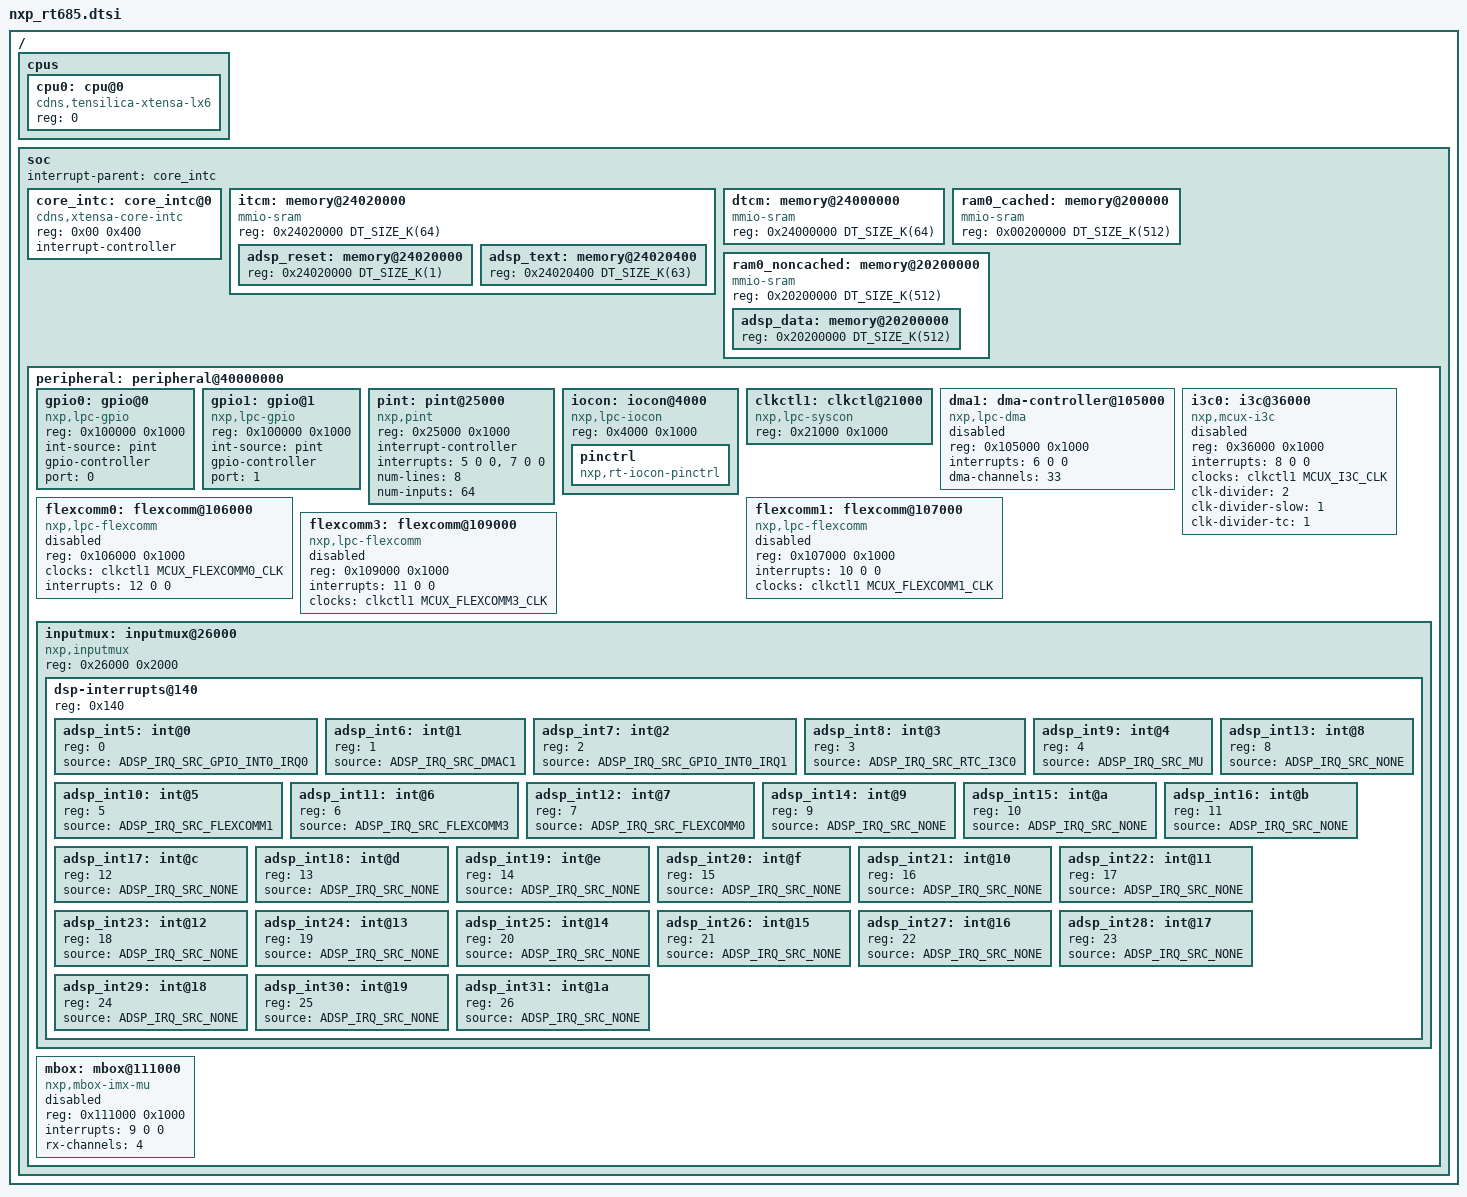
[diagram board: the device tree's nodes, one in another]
/*
 * Copyright (c) 2023 NXP.
 * SPDX-License-Identifier: Apache-2.0
 */

#include <xtensa/xtensa.dtsi>
#include <mem.h>
#include <zephyr/dt-bindings/clock/mcux_lpc_syscon_clock.h>
#include <zephyr/dt-bindings/misc/nxp-inputmux-rt6xx.h>
#include <zephyr/dt-bindings/input/input-event-codes.h>

/ {
	cpus {
		#address-cells = <1>;
		#size-cells = <0>;

		cpu0: cpu@0 {
			device_type = "cpu";
			compatible = "cdns,tensilica-xtensa-lx6";
			reg = <0>;
		};
	};

	soc {
		interrupt-parent = <&core_intc>;

		/*
		 * Dummy interrupt controller node - IRQs are handled directly by soc.c if
		 * building for the RT685 DSP.
		 *
		 * Be sure to configure the inputmux node for appropriate interrupt routing.
		 */
		core_intc: core_intc@0 {
			compatible = "cdns,xtensa-core-intc";
			reg = <0x00 0x400>;
			interrupt-controller;
			#interrupt-cells = <3>;
		};

		itcm: memory@24020000 {
			#address-cells = <1>;
			#size-cells = <1>;
			device_type = "memory";
			compatible = "mmio-sram";

			reg = <0x24020000 DT_SIZE_K(64)>;

			adsp_reset: memory@24020000 {
				reg = <0x24020000 DT_SIZE_K(1)>;
			};

			adsp_text: memory@24020400 {
				reg = <0x24020400 DT_SIZE_K(63)>;
			};
		};

		dtcm: memory@24000000 {
			#address-cells = <1>;
			#size-cells = <1>;
			device_type = "memory";
			compatible = "mmio-sram";

			reg = <0x24000000 DT_SIZE_K(64)>;

			/*adsp_data: memory@24000000 {
				reg = <0x24000000 DT_SIZE_K(64)>;
			};*/
		};

		ram0_cached: memory@200000 {
			#address-cells = <1>;
			#size-cells = <1>;
			device_type = "memory";
			compatible = "mmio-sram";

			reg = <0x00200000 DT_SIZE_K(512)>;

			/*adsp_data: memory@200000 {
				reg = <0x00200000 DT_SIZE_K(512)>;
			};*/
		};

		ram0_noncached: memory@20200000 {
			#address-cells = <1>;
			#size-cells = <1>;
			device_type = "memory";
			compatible = "mmio-sram";

			reg = <0x20200000 DT_SIZE_K(512)>;

			adsp_data: memory@20200000 {
				reg = <0x20200000 DT_SIZE_K(512)>;
			};
		};

		peripheral: peripheral@40000000 {
			ranges = <0x0 0x40000000 0x10000000>;

			#address-cells = <1>;
			#size-cells = <1>;

			gpio0: gpio@0 {
				compatible = "nxp,lpc-gpio";
				reg = <0x100000 0x1000>;
				int-source = "pint";
				gpio-controller;
				#gpio-cells = <2>;
				port = <0>;
			};

			gpio1: gpio@1 {
				compatible = "nxp,lpc-gpio";
				reg = <0x100000 0x1000>;
				int-source = "pint";
				gpio-controller;
				#gpio-cells = <2>;
				port = <1>;
			};

			pint: pint@25000 {
				compatible = "nxp,pint";
				reg = <0x25000 0x1000>;
				interrupt-controller;
				#interrupt-cells = <1>;
				#address-cells = <0>;
				interrupts = <5 0 0>, <7 0 0>;
				num-lines = <8>;
				num-inputs = <64>;
			};

			iocon: iocon@4000 {
				compatible = "nxp,lpc-iocon";
				reg = <0x4000 0x1000>;
				pinctrl: pinctrl {
					compatible = "nxp,rt-iocon-pinctrl";
				};
			};

			clkctl1: clkctl@21000 {
				compatible = "nxp,lpc-syscon";
				reg = <0x21000 0x1000>;
				#clock-cells = <1>;
			};

			dma1: dma-controller@105000 {
				compatible = "nxp,lpc-dma";
				reg = <0x105000 0x1000>;
				interrupts = <6 0 0>;
				dma-channels = <33>;
				status = "disabled";
				#dma-cells = <1>;
			};

			i3c0: i3c@36000 {
				compatible = "nxp,mcux-i3c";
				reg = <0x36000 0x1000>;
				#address-cells = <3>;
				#size-cells = <0>;
				interrupts = <8 0 0>;
				clocks = <&clkctl1 MCUX_I3C_CLK>;
				clk-divider = <2>;
				clk-divider-slow = <1>;
				clk-divider-tc = <1>;
				status = "disabled";
			};

			flexcomm0: flexcomm@106000 {
				compatible = "nxp,lpc-flexcomm";
				reg = <0x106000 0x1000>;
				clocks = <&clkctl1 MCUX_FLEXCOMM0_CLK>;
				interrupts = <12 0 0>;
				status = "disabled";
			};

			flexcomm1: flexcomm@107000 {
				compatible = "nxp,lpc-flexcomm";
				reg = <0x107000 0x1000>;
				interrupts = <10 0 0>;
				clocks = <&clkctl1 MCUX_FLEXCOMM1_CLK>;
				status = "disabled";
			};

			flexcomm3: flexcomm@109000 {
				compatible = "nxp,lpc-flexcomm";
				reg = <0x109000 0x1000>;
				interrupts = <11 0 0>;
				clocks = <&clkctl1 MCUX_FLEXCOMM3_CLK>;
				status = "disabled";
			};

			inputmux: inputmux@26000 {
				compatible = "nxp,inputmux";
				reg = <0x26000 0x2000>;
				status = "okay";

				#address-cells = <1>;
				#size-cells = <0>;

				/*
				 * INPUTMUX interrupt multiplexing - interrupts coming to the
				 * HiFi4 DSP are multiplexed (dynamically routed) rather than
				 * statically wired in the silicon.
				 *
				 * Physical IRQ number also determines its priority - see
				 * Table 1460 of UM11147 (RT6xx User manual).
				 */
				dsp-interrupts@140 {
					reg = <0x140>;

					#address-cells = <1>;
					#size-cells = <0>;

					adsp_int5: int@0 {
						reg = <0>;
						source = <ADSP_IRQ_SRC_GPIO_INT0_IRQ0>;
					};

					adsp_int6: int@1 {
						reg = <1>;
						source = <ADSP_IRQ_SRC_DMAC1>;
					};

					adsp_int7: int@2 {
						reg = <2>;
						source = <ADSP_IRQ_SRC_GPIO_INT0_IRQ1>;
					};

					adsp_int8: int@3 {
						reg = <3>;
						source = <ADSP_IRQ_SRC_RTC_I3C0>;
					};

					adsp_int9: int@4 {
						reg = <4>;
						source = <ADSP_IRQ_SRC_MU>;
					};

					adsp_int10: int@5 {
						reg = <5>;
						source = <ADSP_IRQ_SRC_FLEXCOMM1>;
					};

					adsp_int11: int@6 {
						reg = <6>;
						source = <ADSP_IRQ_SRC_FLEXCOMM3>;
					};

					adsp_int12: int@7 {
						reg = <7>;
						source = <ADSP_IRQ_SRC_FLEXCOMM0>;
					};

					adsp_int13: int@8 {
						reg = <8>;
						source = <ADSP_IRQ_SRC_NONE>;
					};

					adsp_int14: int@9 {
						reg = <9>;
						source = <ADSP_IRQ_SRC_NONE>;
					};

					adsp_int15: int@a {
						reg = <10>;
						source = <ADSP_IRQ_SRC_NONE>;
					};

					adsp_int16: int@b {
						reg = <11>;
						source = <ADSP_IRQ_SRC_NONE>;
					};

					adsp_int17: int@c {
						reg = <12>;
						source = <ADSP_IRQ_SRC_NONE>;
					};

					adsp_int18: int@d {
						reg = <13>;
						source = <ADSP_IRQ_SRC_NONE>;
					};

					adsp_int19: int@e {
						reg = <14>;
						source = <ADSP_IRQ_SRC_NONE>;
					};

					adsp_int20: int@f {
						reg = <15>;
						source = <ADSP_IRQ_SRC_NONE>;
					};

					adsp_int21: int@10 {
						reg = <16>;
						source = <ADSP_IRQ_SRC_NONE>;
					};

					adsp_int22: int@11 {
						reg = <17>;
						source = <ADSP_IRQ_SRC_NONE>;
					};

					adsp_int23: int@12 {
						reg = <18>;
						source = <ADSP_IRQ_SRC_NONE>;
					};

					adsp_int24: int@13 {
						reg = <19>;
						source = <ADSP_IRQ_SRC_NONE>;
					};

					adsp_int25: int@14 {
						reg = <20>;
						source = <ADSP_IRQ_SRC_NONE>;
					};

					adsp_int26: int@15 {
						reg = <21>;
						source = <ADSP_IRQ_SRC_NONE>;
					};

					adsp_int27: int@16 {
						reg = <22>;
						source = <ADSP_IRQ_SRC_NONE>;
					};

					adsp_int28: int@17 {
						reg = <23>;
						source = <ADSP_IRQ_SRC_NONE>;
					};

					adsp_int29: int@18 {
						reg = <24>;
						source = <ADSP_IRQ_SRC_NONE>;
					};

					adsp_int30: int@19 {
						reg = <25>;
						source = <ADSP_IRQ_SRC_NONE>;
					};

					adsp_int31: int@1a {
						reg = <26>;
						source = <ADSP_IRQ_SRC_NONE>;
					};
				};
			};

			mbox: mbox@111000{
				#mbox-cells = <1>;

				compatible = "nxp,mbox-imx-mu";
				reg = <0x111000 0x1000>;
				
				interrupts = <9 0 0>;
				rx-channels = <4>;
				
				status = "disabled";
			};
		};
	};
};
